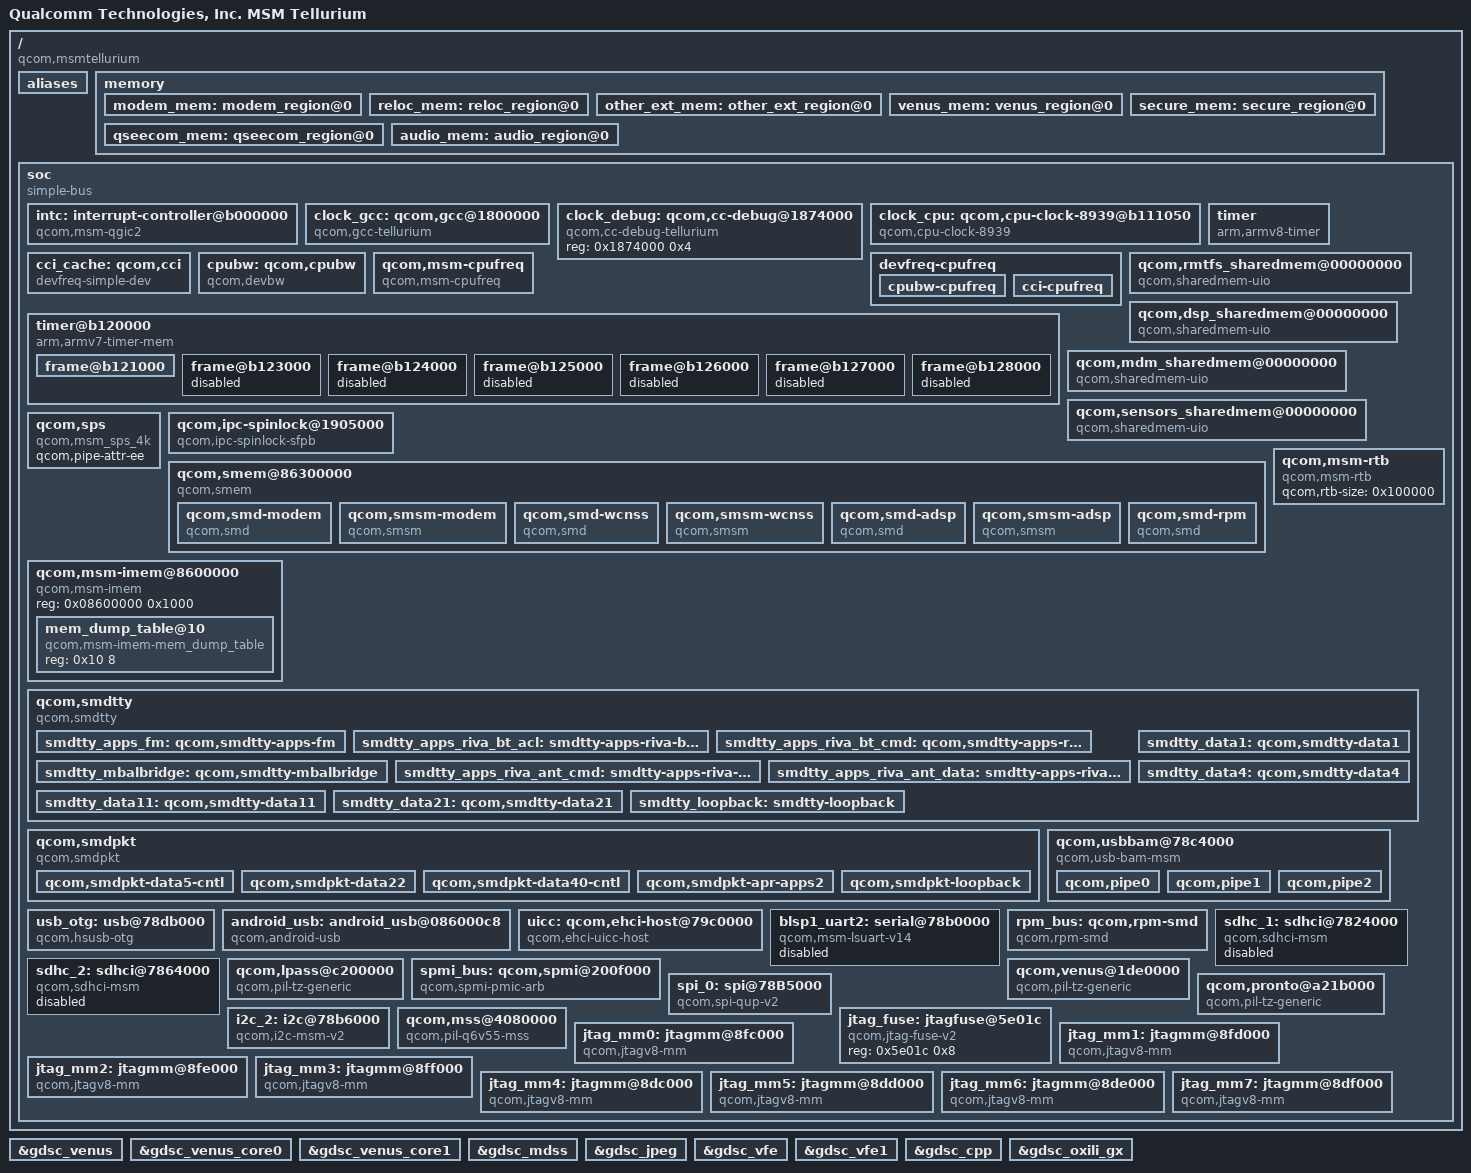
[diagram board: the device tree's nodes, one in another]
/*
 * Copyright (c) 2014-2015, The Linux Foundation. All rights reserved.
 *
 * This program is free software; you can redistribute it and/or modify
 * it under the terms of the GNU General Public License version 2 and
 * only version 2 as published by the Free Software Foundation.
 *
 * This program is distributed in the hope that it will be useful,
 * but WITHOUT ANY WARRANTY; without even the implied warranty of
 * MERCHANTABILITY or FITNESS FOR A PARTICULAR PURPOSE.  See the
 * GNU General Public License for more details.
 */

#include "skeleton64.dtsi"
#include <dt-bindings/clock/msm-clocks-tellurium.h>

/ {
	model = "Qualcomm Technologies, Inc. MSM Tellurium";
	compatible = "qcom,msmtellurium";
	qcom,msm-id = <264 0x0>;
	interrupt-parent = <&intc>;

	aliases {
		sdhc1 = &sdhc_1; /* SDC1 eMMC slot */
		sdhc2 = &sdhc_2; /* SDC2 SD card slot */
		spi0 = &spi_0;
		i2c2 = &i2c_2;
	};

	memory {
		#address-cells = <2>;
		#size-cells = <2>;

		modem_mem: modem_region@0 {
			linux,reserve-contiguous-region;
			linux,reserve-region;
			linux,remove-completely;
			reg = <0x0 0x86800000 0x0 0x03a00000>;
			label = "modem_mem";
		};

		reloc_mem: reloc_region@0 {
			linux,reserve-contiguous-region;
			linux,reserve-region;
			linux,remove-completely;
			reg = <0x0 0x8a200000 0x0 0x1500000>;
			label = "reloc_mem";
		};

		other_ext_mem: other_ext_region@0 {
			linux,reserve-contiguous-region;
			linux,reserve-region;
			linux,remove-completely;
			reg = <0x0 0x86000000 0x0 0x0800000>;
			label = "other_ext_mem";
		};

		venus_mem: venus_region@0 {
			linux,reserve-contiguous-region;
			linux,memory-limit = <0x90000000>;
			reg = <0 0 0 0x0500000>;
			label = "venus_mem";
		};

		secure_mem: secure_region@0 {
			linux,reserve-contiguous-region;
			reg = <0 0 0 0x6D00000>;
			label = "secure_mem";
		};

		qseecom_mem: qseecom_region@0 {
			linux,reserve-contiguous-region;
			reg = <0 0 0 0x1000000>;
			label = "qseecom_mem";
		};

		audio_mem: audio_region@0 {
			linux,reserve-contiguous-region;
			reg = <0 0 0 0x314000>;
			label = "audio_mem";
		};
	};

	aliases {
		/* smdtty devices */
		smd1 = &smdtty_apps_fm;
		smd2 = &smdtty_apps_riva_bt_acl;
		smd3 = &smdtty_apps_riva_bt_cmd;
		smd4 = &smdtty_mbalbridge;
		smd5 = &smdtty_apps_riva_ant_cmd;
		smd6 = &smdtty_apps_riva_ant_data;
		smd7 = &smdtty_data1;
		smd8 = &smdtty_data4;
		smd11 = &smdtty_data11;
		smd21 = &smdtty_data21;
		smd36 = &smdtty_loopback;
	};

	soc: soc { };
};

#include "msmtellurium-ion.dtsi"
#include "msmtellurium-iommu.dtsi"
#include "msm8939-cpu.dtsi"
#include "msmtellurium-pinctrl.dtsi"
#include "msmtellurium-smp2p.dtsi"
#include "msmtellurium-ipcrouter.dtsi"
#include "msm-gdsc-8916.dtsi"
#include "msmtellurium-coresight.dtsi"
#include "msmtellurium-bus.dtsi"

&soc {
	#address-cells = <1>;
	#size-cells = <1>;
	ranges = <0 0 0 0xffffffff>;
	compatible = "simple-bus";

	intc: interrupt-controller@b000000 {
		compatible = "qcom,msm-qgic2";
		interrupt-controller;
		#interrupt-cells = <3>;
		reg = <0x0b000000 0x1000>,
		      <0x0b002000 0x1000>;
	};

	clock_gcc: qcom,gcc@1800000 {
		compatible = "qcom,gcc-tellurium";
		reg = <0x1800000 0x80000>,
			<0xb116000 0x00040>,
			<0xb016000 0x00040>,
			<0xb1d0000 0x00040>;
		reg-names = "cc_base", "apcs_c0_base",
			"apcs_c1_base", "apcs_cci_base";
		vdd_dig-supply = <&pmtellurium_s2_corner>;
		vdd_sr2_dig-supply = <&pmtellurium_s2_corner_ao>;
		vdd_sr2_pll-supply = <&pmtellurium_l7_ao>;
		vdd_hf_dig-supply = <&pmtellurium_s2_corner_ao>;
		vdd_hf_pll-supply = <&pmtellurium_l7_ao>;
		#clock-cells = <1>;
	};

	clock_debug: qcom,cc-debug@1874000 {
		compatible = "qcom,cc-debug-tellurium";
		reg = <0x1874000 0x4>;
		reg-names = "cc_base";
		#clock-cells = <1>;
	};

	clock_cpu: qcom,cpu-clock-8939@b111050 {
		compatible = "qcom,cpu-clock-8939";
		reg =   <0xb111050 0x8>,
			<0xb011050 0x8>,
			<0xb1d1050 0x8>;
		reg-names = "apcs-c0-rcg-base", "apcs-c1-rcg-base",
				"apcs-cci-rcg-base";
		vdd-c0-supply = <&apc_vreg_corner>;
		vdd-c1-supply = <&apc_vreg_corner>;
		vdd-cci-supply = <&apc_vreg_corner>;
		clocks = <&clock_gcc clk_gpll0_ao_clk_src>,
			 <&clock_gcc clk_a53ss_c0_pll>,
			 <&clock_gcc clk_gpll0_ao_clk_src>,
			 <&clock_gcc clk_a53ss_c1_pll>,
			 <&clock_gcc clk_gpll0_ao_clk_src>,
			 <&clock_gcc clk_a53ss_cci_pll>;
		clock-names = "clk-c0-4", "clk-c0-5",
				"clk-c1-4", "clk-c1-5",
				"clk-cci-4", "clk-cci-5";
		qcom,speed0-bin-v0-c0 =
			<          0 0>,
			<  249600000 1>,
			<  499200000 2>,
			<  998400000 3>;

		qcom,speed0-bin-v0-c1 =
			<          0 0>,
			<  400000000 1>,
			<  800000000 2>,
			< 1536000000 3>;

		qcom,speed0-bin-v0-cci =
			<          0 0>,
			<  230400000 1>,
			<  460800000 2>,
			<  595200000 3>;
		#clock-cells = <1>;
	};

	timer {
		compatible = "arm,armv8-timer";
		interrupts = <1 2 0xff08>,
			     <1 3 0xff08>,
			     <1 4 0xff08>,
			     <1 1 0xff08>;
		clock-frequency = <19200000>;
	};

	cci_cache: qcom,cci {
		compatible = "devfreq-simple-dev";
		clock-names = "devfreq_clk";
		clocks = <&clock_cpu clk_a53ssmux_cci>;
		governor = "cpufreq";
		freq-tbl-khz =
			<  200000 >,
			<  297600 >,
			<  400000 >,
			<  595200 >;
	};

	cpubw: qcom,cpubw {
		compatible = "qcom,devbw";
		governor = "cpufreq";
		qcom,src-dst-ports = <1 512>;
		qcom,active-only;
		qcom,bw-tbl =
			<   762 /*  100   MHz */ >,
			<  1336 /*  175.2 MHz */ >,
			<  1977 /*  259.2 MHz */ >,
			<  2673 /*  350.4 MHz */ >,
			<  3564 /*  467.2 MHz */ >;
	};

	devfreq-cpufreq {
		cpubw-cpufreq {
		target-dev = <&cpubw>;
		cpu-to-dev-map-0 =
			<  200000   762 >,
			<  800000  1336 >,
			<  1113600 2673 >,
			<  1536000 3564 >;
		cpu-to-dev-map-4 =
			<  200000  762 >,
			<  499200 1336 >,
			<  800000 2673 >,
			<  998400 3564 >;
		};

		cci-cpufreq {
		target-dev = <&cci_cache>;
		cpu-to-dev-map-0 =
			<  400000  200000 >,
			< 1113600  297600 >,
			< 1536000  595200 >;
		cpu-to-dev-map-4 =
			<  249600 200000 >,
			<  800000 297600 >,
			<  998400 595200 >;
		};
	};


	qcom,msm-cpufreq {
		compatible = "qcom,msm-cpufreq";
		clock-names = "l2_clk", "cpu0_clk", "cpu1_clk", "cpu2_clk",
				"cpu3_clk", "cpu4_clk", "cpu5_clk",
				"cpu6_clk", "cpu7_clk";
		clocks = <&clock_cpu clk_a53ssmux_cci>,
			 <&clock_cpu clk_a53ssmux_bc>,
			 <&clock_cpu clk_a53ssmux_bc>,
			 <&clock_cpu clk_a53ssmux_bc>,
			 <&clock_cpu clk_a53ssmux_bc>,
			 <&clock_cpu clk_a53ssmux_lc>,
			 <&clock_cpu clk_a53ssmux_lc>,
			 <&clock_cpu clk_a53ssmux_lc>,
			 <&clock_cpu clk_a53ssmux_lc>;

		qcom,cpufreq-table-0 =
			 <  200000 >,
			 <  345600 >,
			 <  400000 >,
			 <  533330 >,
			 <  800000 >,
                         <  960000 >,
			 < 1113600 >,
			 < 1344000 >,
			 < 1497600 >,
			 < 1536000 >;
		qcom,cpufreq-table-4 =
			 <  200000 >,
			 <  249600 >,
			 <  499200 >,
			 <  800000 >,
			 <  998400 >;
	};

	timer@b120000 {
		#address-cells = <1>;
		#size-cells = <1>;
		ranges;
		compatible = "arm,armv7-timer-mem";
		reg = <0xb120000 0x1000>;
		clock-frequency = <19200000>;

		frame@b121000 {
			frame-number = <0>;
			interrupts = <0 8 0x4>,
				     <0 7 0x4>;
			reg = <0xb121000 0x1000>,
			      <0xb122000 0x1000>;
		};

		frame@b123000 {
			frame-number = <1>;
			interrupts = <0 9 0x4>;
			reg = <0xb123000 0x1000>;
			status = "disabled";
		};

		frame@b124000 {
			frame-number = <2>;
			interrupts = <0 10 0x4>;
			reg = <0xb124000 0x1000>;
			status = "disabled";
		};

		frame@b125000 {
			frame-number = <3>;
			interrupts = <0 11 0x4>;
			reg = <0xb125000 0x1000>;
			status = "disabled";
		};

		frame@b126000 {
			frame-number = <4>;
			interrupts = <0 12 0x4>;
			reg = <0xb126000 0x1000>;
			status = "disabled";
		};

		frame@b127000 {
			frame-number = <5>;
			interrupts = <0 13 0x4>;
			reg = <0xb127000 0x1000>;
			status = "disabled";
		};

		frame@b128000 {
			frame-number = <6>;
			interrupts = <0 14 0x4>;
			reg = <0xb128000 0x1000>;
			status = "disabled";
		};
	};

	qcom,rmtfs_sharedmem@00000000 {
		compatible = "qcom,sharedmem-uio";
		reg = <0x00000000 0x00180000>;
		reg-names = "rmtfs";
		qcom,client-id = <0x00000001>;
	};

	qcom,dsp_sharedmem@00000000 {
		compatible = "qcom,sharedmem-uio";
		reg = <0x00000000 0x00010000>;
		reg-names = "rfsa_dsp";
		qcom,client-id = <0x011013ec>;
	};

	qcom,mdm_sharedmem@00000000 {
		compatible = "qcom,sharedmem-uio";
		reg = <0x00000000 0x00010000>;
		reg-names = "rfsa_mdm";
		qcom,client-id = <0x011013ed>;
	};

	qcom,sensors_sharedmem@00000000 {
		compatible = "qcom,sharedmem-uio";
		reg = <0x00000000 0x00010000>;
		reg-names = "rfsa_sensor";
		qcom,client-id = <0x011013ee>;
	};

	qcom,sps {
		compatible = "qcom,msm_sps_4k";
		qcom,pipe-attr-ee;
	};

	qcom,ipc-spinlock@1905000 {
		compatible = "qcom,ipc-spinlock-sfpb";
		reg = <0x1905000 0x8000>;
		qcom,num-locks = <8>;
	};

	qcom,smem@86300000 {
		compatible = "qcom,smem";
		reg = <0x86300000 0x100000>,
			<0x0b011008 0x4>,
			<0x60000 0x8000>,
			<0x193D000 0x8>;
		reg-names = "smem", "irq-reg-base", "aux-mem1", "smem_targ_info_reg";
		qcom,mpu-enabled;

		qcom,smd-modem {
			compatible = "qcom,smd";
			qcom,smd-edge = <0>;
			qcom,smd-irq-offset = <0x0>;
			qcom,smd-irq-bitmask = <0x1000>;
			interrupts = <0 25 1>;
			label = "modem";
		};

		qcom,smsm-modem {
			compatible = "qcom,smsm";
			qcom,smsm-edge = <0>;
			qcom,smsm-irq-offset = <0x0>;
			qcom,smsm-irq-bitmask = <0x2000>;
			interrupts = <0 26 1>;
		};

		qcom,smd-wcnss {
			compatible = "qcom,smd";
			qcom,smd-edge = <6>;
			qcom,smd-irq-offset = <0x0>;
			qcom,smd-irq-bitmask = <0x20000>;
			interrupts = <0 142 1>;
			label = "wcnss";
		};

		qcom,smsm-wcnss {
			compatible = "qcom,smsm";
			qcom,smsm-edge = <6>;
			qcom,smsm-irq-offset = <0x0>;
			qcom,smsm-irq-bitmask = <0x80000>;
			interrupts = <0 144 1>;
		};

		qcom,smd-adsp {
			compatible = "qcom,smd";
			qcom,smd-edge = <1>;
			qcom,smd-irq-offset = <0x0>;
			qcom,smd-irq-bitmask = <0x100>;
			interrupts = <0 289 1>;
			label = "adsp";
		};

		qcom,smsm-adsp {
			compatible = "qcom,smsm";
			qcom,smsm-edge = <1>;
			qcom,smsm-irq-offset = <0x0>;
			qcom,smsm-irq-bitmask = <0x200>;
			interrupts = <0 290 1>;
		};

		qcom,smd-rpm {
			compatible = "qcom,smd";
			qcom,smd-edge = <15>;
			qcom,smd-irq-offset = <0x0>;
			qcom,smd-irq-bitmask = <0x1>;
			interrupts = <0 168 1>;
			label = "rpm";
			qcom,irq-no-suspend;
			qcom,not-loadable;
		};
	};

	qcom,msm-rtb {
		compatible = "qcom,msm-rtb";
		qcom,rtb-size = <0x100000>; /* 1M EBI1 buffer */
	};

	qcom,msm-imem@8600000 {
		compatible = "qcom,msm-imem";
		reg = <0x08600000 0x1000>; /* Address and size of IMEM */
		ranges = <0x0 0x08600000 0x1000>;
		#address-cells = <1>;
		#size-cells = <1>;

		mem_dump_table@10 {
			compatible = "qcom,msm-imem-mem_dump_table";
			reg = <0x10 8>;
		};
	};

	qcom,smdtty {
		compatible = "qcom,smdtty";

		smdtty_apps_fm: qcom,smdtty-apps-fm {
			qcom,smdtty-remote = "wcnss";
			qcom,smdtty-port-name = "APPS_FM";
		};

		smdtty_apps_riva_bt_acl: smdtty-apps-riva-bt-acl {
			qcom,smdtty-remote = "wcnss";
			qcom,smdtty-port-name = "APPS_RIVA_BT_ACL";
		};

		smdtty_apps_riva_bt_cmd: qcom,smdtty-apps-riva-bt-cmd {
			qcom,smdtty-remote = "wcnss";
			qcom,smdtty-port-name = "APPS_RIVA_BT_CMD";
		};

		smdtty_mbalbridge: qcom,smdtty-mbalbridge {
			qcom,smdtty-remote = "modem";
			qcom,smdtty-port-name = "MBALBRIDGE";
		};

		smdtty_apps_riva_ant_cmd: smdtty-apps-riva-ant-cmd {
			qcom,smdtty-remote = "wcnss";
			qcom,smdtty-port-name = "APPS_RIVA_ANT_CMD";
		};

		smdtty_apps_riva_ant_data: smdtty-apps-riva-ant-data {
			qcom,smdtty-remote = "wcnss";
			qcom,smdtty-port-name = "APPS_RIVA_ANT_DATA";
		};

		smdtty_data1: qcom,smdtty-data1 {
			qcom,smdtty-remote = "modem";
			qcom,smdtty-port-name = "DATA1";
		};

		smdtty_data4: qcom,smdtty-data4 {
			qcom,smdtty-remote = "modem";
			qcom,smdtty-port-name = "DATA4";
		};

		smdtty_data11: qcom,smdtty-data11 {
			qcom,smdtty-remote = "modem";
			qcom,smdtty-port-name = "DATA11";
		};

		smdtty_data21: qcom,smdtty-data21 {
			qcom,smdtty-remote = "modem";
			qcom,smdtty-port-name = "DATA21";
		};

		smdtty_loopback: smdtty-loopback {
			qcom,smdtty-remote = "modem";
			qcom,smdtty-port-name = "LOOPBACK";
			qcom,smdtty-dev-name = "LOOPBACK_TTY";
		};
	};

	qcom,smdpkt {
		compatible = "qcom,smdpkt";

		qcom,smdpkt-data5-cntl {
			qcom,smdpkt-remote = "modem";
			qcom,smdpkt-port-name = "DATA5_CNTL";
			qcom,smdpkt-dev-name = "smdcntl0";
		};

		qcom,smdpkt-data22 {
			qcom,smdpkt-remote = "modem";
			qcom,smdpkt-port-name = "DATA22";
			qcom,smdpkt-dev-name = "smd22";
		};

		qcom,smdpkt-data40-cntl {
			qcom,smdpkt-remote = "modem";
			qcom,smdpkt-port-name = "DATA40_CNTL";
			qcom,smdpkt-dev-name = "smdcntl8";
		};

		qcom,smdpkt-apr-apps2 {
			qcom,smdpkt-remote = "modem";
			qcom,smdpkt-port-name = "apr_apps2";
			qcom,smdpkt-dev-name = "apr_apps2";
		};

		qcom,smdpkt-loopback {
			qcom,smdpkt-remote = "modem";
			qcom,smdpkt-port-name = "LOOPBACK";
			qcom,smdpkt-dev-name = "smd_pkt_loopback";
		};
	};

	qcom,usbbam@78c4000 {
		compatible = "qcom,usb-bam-msm";
		reg = <0x78c4000 0x17000>;
		reg-names = "hsusb";
		interrupts = <0 135 0>;
		interrupt-names = "hsusb";
		qcom,usb-bam-num-pipes = <4>;
		qcom,usb-bam-fifo-baseaddr = <0x08605000>;
		qcom,ignore-core-reset-ack;
		qcom,disable-clk-gating;
		qcom,usb-bam-max-mbps-highspeed = <400>;

		qcom,pipe0 {
			label = "hsusb-ipa-out-0";
			qcom,usb-bam-mem-type = <2>;
			qcom,bam-type = <1>;
			qcom,dir = <0>;
			qcom,pipe-num = <0>;
			qcom,peer-bam = <2>;
			qcom,src-bam-physical-address = <0x78c4000>;
			qcom,src-bam-pipe-index = <1>;
			qcom,data-fifo-size = <0x8000>;
			qcom,descriptor-fifo-size = <0x2000>;
			qcom,reset-bam-on-connect;
		};
		qcom,pipe1 {
			label = "hsusb-ipa-in-0";
			qcom,usb-bam-mem-type = <2>;
			qcom,bam-type = <1>;
			qcom,dir = <1>;
			qcom,pipe-num = <0>;
			qcom,peer-bam = <2>;
			qcom,dst-bam-physical-address = <0x78c4000>;
			qcom,dst-bam-pipe-index = <0>;
			qcom,data-fifo-size = <0x8000>;
			qcom,descriptor-fifo-size = <0x2000>;
			qcom,reset-bam-on-connect;
		};

		qcom,pipe2 {
			label = "hsusb-qdss-in-0";
			qcom,usb-bam-mem-type = <3>;
			qcom,bam-type = <1>;
			qcom,dir = <1>;
			qcom,pipe-num = <0>;
			qcom,peer-bam = <1>;
			qcom,src-bam-physical-address = <0x884000>;
			qcom,src-bam-pipe-index = <0>;
			qcom,dst-bam-physical-address = <0x78c4000>;
			qcom,dst-bam-pipe-index = <0>;
			qcom,data-fifo-offset = <0x0>;
			qcom,data-fifo-size = <0xe00>;
			qcom,descriptor-fifo-offset = <0xe00>;
			qcom,descriptor-fifo-size = <0x200>;
			qcom,reset-bam-on-connect;
		};
	};

	usb_otg: usb@78db000 {
		compatible = "qcom,hsusb-otg";
		reg = <0x78db000 0x400>, <0x6c000 0x200>;
		reg-names = "core", "phy_csr";

		interrupts = <0 134 0>,<0 140 0>;
		interrupt-names = "core_irq", "async_irq";

		hsusb_vdd_dig-supply = <&pmtellurium_l2>;
		HSUSB_1p8-supply = <&pmtellurium_l7>;
		HSUSB_3p3-supply = <&pmtellurium_l13>;
		qcom,vdd-voltage-level = <0 1200000 1200000>;

		qcom,hsusb-otg-phy-type = <3>; /* SNPS Femto PHY */
		qcom,hsusb-otg-mode = <1>; /* DEVICE only */
		qcom,hsusb-otg-otg-control = <2>; /* PMIC */
		qcom,dp-manual-pullup;
		qcom,hsusb-otg-disable-reset;
		qcom,hsusb-otg-mpm-dpsehv-int = <49>;
		qcom,hsusb-otg-mpm-dmsehv-int = <58>;
		qcom,phy-dvdd-always-on;

		qcom,msm-bus,name = "usb2";
		qcom,msm-bus,num-cases = <3>;
		qcom,msm-bus,num-paths = <1>;
		qcom,msm-bus,vectors-KBps =
				<87 512 0 0>,
				<87 512 80000 0>,
				<87 512 6000  6000>;
		clocks = <&clock_gcc clk_gcc_usb_hs_ahb_clk>,
			 <&clock_gcc clk_gcc_usb_hs_system_clk>,
			 <&clock_gcc clk_gcc_usb2a_phy_sleep_clk>,
			 <&clock_gcc clk_bimc_usb_a_clk>,
			 <&clock_gcc clk_snoc_usb_a_clk>,
			 <&clock_gcc clk_pnoc_usb_a_clk>,
			 <&clock_gcc clk_gcc_qusb2_phy_clk>,
			 <&clock_gcc clk_gcc_usb2_hs_phy_only_clk>,
			 <&clock_gcc clk_gcc_usb_hs_phy_cfg_ahb_clk>,
			 <&clock_gcc clk_xo_otg_clk>;
		clock-names = "iface_clk", "core_clk", "sleep_clk",
				"bimc_clk", "snoc_clk", "pcnoc_clk",
				"phy_reset_clk", "phy_por_clk", "phy_csr_clk",
				"xo";
		qcom,bus-clk-rate = <350400000 200000000 100000000>;
	};

	android_usb: android_usb@086000c8 {
		compatible = "qcom,android-usb";
		reg = <0x086000c8 0xc8>;
		qcom,pm-qos-latency = <2 1001 12701>;
		qcom,streaming-func = "mtp";
		qcom,android-usb-uicc-nluns = /bits/ 8 <1>;
	};

	uicc: qcom,ehci-host@79c0000 {
		compatible = "qcom,ehci-uicc-host";
		reg = <0x79c0000 0x400>;
		interrupts = <0 132 0>;

		clocks = <&clock_gcc clk_gcc_usb_fs_ahb_clk>,
			 <&clock_gcc clk_gcc_usb_fs_system_clk>,
			 <&clock_gcc clk_gcc_usb_fs_ic_clk>;
		clock-names = "iface_clk", "core_clk", "alt_core_clk";

		pinctrl-names = "uicc_active", "uicc_sleep";
		pinctrl-0 = <&uicc_active>;
		pinctrl-1 = <&uicc_sleep>;

		qcom,msm-bus,name = "uicc";
		qcom,msm-bus,num-cases = <2>;
		qcom,msm-bus,num-paths = <1>;
		qcom,msm-bus,vectors-KBps =
				<93 512 0 0>,
				<93 512 12000 192000>;
	};

	blsp1_uart2: serial@78b0000 {
		compatible = "qcom,msm-lsuart-v14";
		reg = <0x78b0000 0x200>;
		interrupts = <0 108 0>;
		status = "disabled";
		clocks = <&clock_gcc clk_gcc_blsp1_uart2_apps_clk>,
		<&clock_gcc clk_gcc_blsp1_ahb_clk>;
		clock-names = "core_clk", "iface_clk";
	};

	rpm_bus: qcom,rpm-smd {
		compatible = "qcom,rpm-smd";
		rpm-channel-name = "rpm_requests";
		rpm-channel-type = <15>; /* SMD_APPS_RPM */
		rpm-standalone; /* TODO: remove this after bring up */
	};

	sdhc_1: sdhci@7824000 {
		compatible = "qcom,sdhci-msm";
		reg = <0x7824900 0x11c>, <0x7824000 0x800>;
		reg-names = "hc_mem", "core_mem";

		interrupts = <0 123 0>, <0 138 0>;
		interrupt-names = "hc_irq", "pwr_irq";

		qcom,bus-width = <8>;

		qcom,cpu-dma-latency-us = <701>;
		clocks = <&clock_gcc clk_gcc_sdcc1_ahb_clk>,
			 <&clock_gcc clk_gcc_sdcc1_apps_clk>;
		clock-names = "iface_clk", "core_clk";

		qcom,clk-rates = <400000 25000000 50000000 100000000 177770000>;
		qcom,bus-speed-mode = "HS200_1p8v", "DDR_1p8v";

		status = "disabled";
	};

	sdhc_2: sdhci@7864000 {
		compatible = "qcom,sdhci-msm";
		reg = <0x7864900 0x11c>, <0x7864000 0x800>;
		reg-names = "hc_mem", "core_mem";

		interrupts = <0 125 0>, <0 221 0>;
		interrupt-names = "hc_irq", "pwr_irq";

		qcom,bus-width = <4>;

		qcom,cpu-dma-latency-us = <701>;
		clocks = <&clock_gcc clk_gcc_sdcc2_ahb_clk>,
			 <&clock_gcc clk_gcc_sdcc2_apps_clk>;
		clock-names = "iface_clk", "core_clk";

		qcom,clk-rates = <400000 25000000 50000000 100000000 200000000>;

		status = "disabled";
	};

	qcom,lpass@c200000 {
		compatible = "qcom,pil-tz-generic";
		reg = <0xc200000 0x00100>;
		interrupts = <0 293 1>;

		vdd_cx-supply = <&pmtellurium_s2_corner>;
		qcom,proxy-reg-names = "vdd_cx";
		qcom,vdd_cx-uV-uA = <7 100000>;

		clocks = <&clock_gcc clk_xo_pil_lpass_clk>,
			 <&clock_gcc clk_gcc_crypto_clk>,
			 <&clock_gcc clk_gcc_crypto_ahb_clk>,
			 <&clock_gcc clk_gcc_crypto_axi_clk>,
			 <&clock_gcc clk_crypto_clk_src>;
		clock-names = "xo", "scm_core_clk", "scm_iface_clk",
				"scm_bus_clk", "scm_core_clk_src";
		qcom,proxy-clock-names = "xo", "scm_core_clk", "scm_iface_clk",
				 "scm_bus_clk", "scm_core_clk_src";
		qcom,scm_core_clk_src-freq = <80000000>;

		qcom,pas-id = <1>;
		qcom,proxy-timeout-ms = <10000>;
		qcom,smem-id = <423>;
		qcom,sysmon-id = <1>;
		qcom,ssctl-instance-id = <0x14>;
		qcom,firmware-name = "adsp";

		/* GPIO inputs from lpass */
		qcom,gpio-err-fatal = <&smp2pgpio_ssr_smp2p_2_in 0 0>;
		qcom,gpio-proxy-unvote = <&smp2pgpio_ssr_smp2p_2_in 2 0>;
		qcom,gpio-err-ready = <&smp2pgpio_ssr_smp2p_2_in 1 0>;
		qcom,gpio-stop-ack = <&smp2pgpio_ssr_smp2p_2_in 3 0>;

		/* GPIO output to lpass */
		qcom,gpio-force-stop = <&smp2pgpio_ssr_smp2p_2_out 0 0>;

		linux,contiguous-region = <&reloc_mem>;
	};

	spmi_bus: qcom,spmi@200f000 {
		compatible = "qcom,spmi-pmic-arb";
		reg = <0x200f000 0x1000>,
			<0x2400000 0x800000>,
			<0x2c00000 0x800000>,
			<0x3800000 0x200000>,
			<0x200a000 0x2100>;
		reg-names = "core", "chnls", "obsrvr", "intr", "cnfg";
		interrupts = <0 190 0>;
		qcom,pmic-arb-channel = <0>;
		qcom,pmic-arb-max-peripherals = <256>;
		qcom,pmic-arb-max-periph-interrupts = <224>;
		qcom,pmic-arb-ee = <0>;
		#interrupt-cells = <3>;
		interrupt-controller;
		#address-cells = <1>;
		#size-cells = <0>;
		cell-index = <0>;
		qcom,not-wakeup; /* Needed until MPM is fully configured. */
	};

	qcom,venus@1de0000 {
		compatible = "qcom,pil-tz-generic";
		reg = <0x1de0000 0x4000>;

		vdd-supply = <&gdsc_venus>;
		qcom,proxy-reg-names = "vdd";

		clocks = <&clock_gcc clk_gcc_venus0_vcodec0_clk>,
			 <&clock_gcc clk_gcc_venus0_ahb_clk>,
			 <&clock_gcc clk_gcc_venus0_axi_clk>,
			 <&clock_gcc clk_gcc_crypto_clk>,
			 <&clock_gcc clk_gcc_crypto_ahb_clk>,
			 <&clock_gcc clk_gcc_crypto_axi_clk>,
			 <&clock_gcc clk_crypto_clk_src>;

		clock-names = "core_clk", "iface_clk", "bus_clk",
				"scm_core_clk", "scm_iface_clk",
				"scm_bus_clk", "scm_core_clk_src";

		qcom,proxy-clock-names = "core_clk", "iface_clk",
					 "bus_clk", "scm_core_clk",
					 "scm_iface_clk", "scm_bus_clk",
					 "scm_core_clk_src";
		qcom,scm_core_clk_src-freq = <80000000>;

		qcom,pas-id = <9>;
		qcom,proxy-timeout-ms = <5000>;
		qcom,firmware-name = "venus";
		linux,contiguous-region = <&venus_mem>;
	};

	spi_0: spi@78B5000 { /* BLSP1 QUP0 */
		compatible = "qcom,spi-qup-v2";
		#address-cells = <1>;
		#size-cells = <0>;
		reg-names = "spi_physical", "spi_bam_physical";
		reg = <0x78B5000 0x600>,
		      <0x7884000 0x23000>;
		interrupt-names = "spi_irq", "spi_bam_irq";
		interrupts = <0 95 0>, <0 238 0>;
		spi-max-frequency = <19200000>;
		pinctrl-names = "spi_default", "spi_sleep";
		pinctrl-0 = <&spi0_default &spi0_cs0_active>;
		pinctrl-1 = <&spi0_sleep &spi0_cs0_sleep>;
		clocks = <&clock_gcc clk_gcc_blsp1_ahb_clk>,
			 <&clock_gcc clk_gcc_blsp1_qup1_spi_apps_clk>;
		clock-names = "iface_clk", "core_clk";
		qcom,infinite-mode = <0>;
		qcom,use-bam;
		qcom,use-pinctrl;
		qcom,ver-reg-exists;
		qcom,bam-consumer-pipe-index = <4>;
		qcom,bam-producer-pipe-index = <5>;
		qcom,master-id = <86>;
	};

	qcom,pronto@a21b000 {
		compatible = "qcom,pil-tz-generic";
		reg = <0x0a21b000 0x3000>;
		interrupts = <0 149 1>;

		vdd_pronto_pll-supply = <&pmtellurium_l7>;
		proxy-reg-names = "vdd_pronto_pll";
		vdd_pronto_pll-uV-uA = <1800000 18000>;
		clocks = <&clock_gcc clk_xo_pil_pronto_clk>,
			 <&clock_gcc clk_gcc_crypto_clk>,
			 <&clock_gcc clk_gcc_crypto_ahb_clk>,
			 <&clock_gcc clk_gcc_crypto_axi_clk>,
			 <&clock_gcc clk_crypto_clk_src>;

		clock-names = "xo", "scm_core_clk", "scm_iface_clk",
				"scm_bus_clk", "scm_core_clk_src";
		qcom,proxy-clock-names = "xo", "scm_core_clk", "scm_iface_clk",
				 "scm_bus_clk", "scm_core_clk_src";
		qcom,scm_core_clk_src = <80000000>;

		qcom,pas-id = <6>;
		qcom,proxy-timeout-ms = <10000>;
		qcom,smem-id = <422>;
		qcom,sysmon-id = <6>;
		qcom,ssctl-instance-id = <0x13>;
		qcom,firmware-name = "wcnss";

		/* GPIO inputs from wcnss */
		qcom,gpio-err-fatal = <&smp2pgpio_ssr_smp2p_4_in 0 0>;
		qcom,gpio-err-ready = <&smp2pgpio_ssr_smp2p_4_in 1 0>;
		qcom,gpio-proxy-unvote = <&smp2pgpio_ssr_smp2p_4_in 2 0>;
		qcom,gpio-stop-ack = <&smp2pgpio_ssr_smp2p_4_in 3 0>;

                /* GPIO output to wcnss */
		qcom,gpio-force-stop = <&smp2pgpio_ssr_smp2p_4_out 0 0>;
		linux,contiguous-region = <&reloc_mem>;
	};

	i2c_2: i2c@78b6000 { /* BLSP1 QUP2 */
		compatible = "qcom,i2c-msm-v2";
		#address-cells = <1>;
		#size-cells = <0>;
		reg-names = "qup_phys_addr", "bam_phys_addr";
		reg = <0x78b6000 0x1000>,
		      <0x7884000 0x1F000>;
		interrupt-names = "qup_irq", "bam_irq";
		interrupts = <0 96 0>, <0 238 0>;
		qcom,clk-freq-out = <400000>;
		qcom,clk-freq-in  = <19200000>;
		clock-names = "iface_clk", "core_clk";
		clocks = <&clock_gcc clk_gcc_blsp1_ahb_clk>,
			 <&clock_gcc clk_gcc_blsp1_qup2_i2c_apps_clk>;

		pinctrl-names = "i2c_active", "i2c_sleep";
		pinctrl-0 = <&i2c_2_active>;
		pinctrl-1 = <&i2c_2_sleep>;
		qcom,noise-rjct-scl = <0>;
		qcom,noise-rjct-sda = <0>;
		qcom,bam-pipe-idx-cons = <6>;
		qcom,bam-pipe-idx-prod = <7>;
		qcom,master-id = <86>;
	};

	qcom,mss@4080000 {
		compatible = "qcom,pil-q6v55-mss";
		reg = <0x04080000 0x100>,
		      <0x0194f000 0x010>,
		      <0x01950000 0x008>,
		      <0x01951000 0x008>,
		      <0x04020000 0x040>,
		      <0x01871000 0x004>;
		reg-names = "qdsp6_base", "halt_q6", "halt_modem", "halt_nc",
				 "rmb_base", "restart_reg";

		interrupts = <0 24 1>;
		vdd_cx-supply = <&pmtellurium_s2_corner>;
		vdd_mx-supply = <&pmtellurium_l3>;
		vdd_mx-uV = <1050000>;
		vdd_pll-supply = <&pmtellurium_l7>;
		qcom,vdd_pll = <1800000>;

		clocks = <&clock_gcc clk_xo_pil_mss_clk>,
			 <&clock_gcc clk_gcc_mss_cfg_ahb_clk>,
			 <&clock_gcc clk_gcc_mss_q6_bimc_axi_clk>,
			 <&clock_gcc clk_gcc_boot_rom_ahb_clk>;
		clock-names = "xo", "iface_clk", "bus_clk", "mem_clk";
		qcom,proxy-clock-names = "xo";
		qcom,active-clock-names = "iface_clk", "bus_clk", "mem_clk";

		qcom,firmware-name = "modem";
		qcom,pil-self-auth;
		qcom,sysmon-id = <0>;
		qcom,ssctl-instance-id = <0x12>;

		/* GPIO inputs from mss */
		qcom,gpio-err-fatal = <&smp2pgpio_ssr_smp2p_1_in 0 0>;
		qcom,gpio-err-ready = <&smp2pgpio_ssr_smp2p_1_in 1 0>;
		qcom,gpio-proxy-unvote = <&smp2pgpio_ssr_smp2p_1_in 2 0>;
		qcom,gpio-stop-ack = <&smp2pgpio_ssr_smp2p_1_in 3 0>;

		/* GPIO output to mss */
		qcom,gpio-force-stop = <&smp2pgpio_ssr_smp2p_1_out 0 0>;
		linux,contiguous-region = <&modem_mem>;
	};

	jtag_fuse: jtagfuse@5e01c {
		compatible = "qcom,jtag-fuse-v2";
		reg = <0x5e01c 0x8>;
		reg-names = "fuse-base";
	};

	jtag_mm0: jtagmm@8fc000 {
		compatible = "qcom,jtagv8-mm";
		reg = <0x8fc000 0x1000>,
		      <0x8f0000 0x1000>;
		reg-names = "etm-base", "debug-base";

		qcom,coresight-jtagmm-cpu = <&CPU0>;

		clocks = <&clock_gcc clk_qdss_clk>,
		         <&clock_gcc clk_qdss_a_clk>;
		clock-names = "core_clk", "core_a_clk";
	};

	jtag_mm1: jtagmm@8fd000 {
		compatible = "qcom,jtagv8-mm";
		reg = <0x8fd000 0x1000>,
		      <0x8f2000 0x1000>;
		reg-names = "etm-base", "debug-base";

		qcom,coresight-jtagmm-cpu = <&CPU1>;

		clocks = <&clock_gcc clk_qdss_clk>,
		         <&clock_gcc clk_qdss_a_clk>;
		clock-names = "core_clk", "core_a_clk";
	};

	jtag_mm2: jtagmm@8fe000 {
		compatible = "qcom,jtagv8-mm";
		reg = <0x8fe000 0x1000>,
		      <0x8f4000 0x1000>;
		reg-names = "etm-base", "debug-base";

		qcom,coresight-jtagmm-cpu = <&CPU2>;

		clocks = <&clock_gcc clk_qdss_clk>,
		         <&clock_gcc clk_qdss_a_clk>;
		clock-names = "core_clk", "core_a_clk";
	};

	jtag_mm3: jtagmm@8ff000 {
		compatible = "qcom,jtagv8-mm";
		reg = <0x8ff000 0x1000>,
		      <0x8f6000 0x1000>;
		reg-names = "etm-base", "debug-base";

		qcom,coresight-jtagmm-cpu = <&CPU3>;

		clocks = <&clock_gcc clk_qdss_clk>,
		         <&clock_gcc clk_qdss_a_clk>;
		clock-names = "core_clk", "core_a_clk";
	};

	jtag_mm4: jtagmm@8dc000 {
		compatible = "qcom,jtagv8-mm";
		reg = <0x8dc000 0x1000>,
		      <0x8d0000 0x1000>;
		reg-names = "etm-base", "debug-base";

		qcom,coresight-jtagmm-cpu = <&CPU4>;

		clocks = <&clock_gcc clk_qdss_clk>,
		         <&clock_gcc clk_qdss_a_clk>;
		clock-names = "core_clk", "core_a_clk";
	};

	jtag_mm5: jtagmm@8dd000 {
		compatible = "qcom,jtagv8-mm";
		reg = <0x8dd000 0x1000>,
		      <0x8d2000 0x1000>;
		reg-names = "etm-base", "debug-base";

		qcom,coresight-jtagmm-cpu = <&CPU5>;

		clocks = <&clock_gcc clk_qdss_clk>,
		         <&clock_gcc clk_qdss_a_clk>;
		clock-names = "core_clk", "core_a_clk";
	};

	jtag_mm6: jtagmm@8de000 {
		compatible = "qcom,jtagv8-mm";
		reg = <0x8de000 0x1000>,
		      <0x8d4000 0x1000>;
		reg-names = "etm-base", "debug-base";

		qcom,coresight-jtagmm-cpu = <&CPU6>;

		clocks = <&clock_gcc clk_qdss_clk>,
		         <&clock_gcc clk_qdss_a_clk>;
		clock-names = "core_clk", "core_a_clk";
	};

	jtag_mm7: jtagmm@8df000 {
		compatible = "qcom,jtagv8-mm";
		reg = <0x8df000 0x1000>,
		      <0x8d6000 0x1000>;
		reg-names = "etm-base", "debug-base";

		qcom,coresight-jtagmm-cpu = <&CPU7>;

		clocks = <&clock_gcc clk_qdss_clk>,
		         <&clock_gcc clk_qdss_a_clk>;
		clock-names = "core_clk", "core_a_clk";
	};
};

&gdsc_venus {
	status = "okay";
};

&gdsc_venus_core0 {
	status = "okay";
};

&gdsc_venus_core1 {
	status = "okay";
};

&gdsc_mdss {
	status = "okay";
};

&gdsc_jpeg {
	status = "okay";
};

&gdsc_vfe {
	status = "okay";
};

&gdsc_vfe1 {
	status = "okay";
};

&gdsc_cpp {
	status = "okay";
};

&gdsc_oxili_gx {
	status = "okay";
};

#include "msmtellurium-regulator.dtsi"
#include "msm-pmtellurium.dtsi"
#include "msm-pmitellurium.dtsi"
